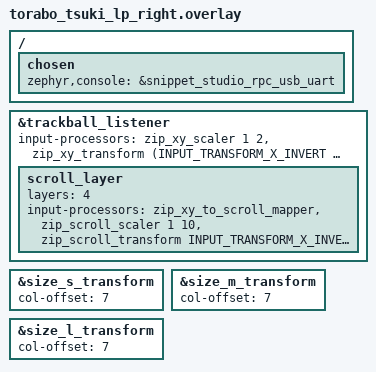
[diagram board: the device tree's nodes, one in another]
#include "torabo_tsuki_lp.dtsi"
#include <input/processors.dtsi>
#include <dt-bindings/zmk/input_transform.h>

/ {
	chosen {
		zephyr,console = &snippet_studio_rpc_usb_uart;
	};
};

&trackball_listener {
    input-processors = <&zip_xy_scaler 1 2
                        &zip_xy_transform (INPUT_TRANSFORM_X_INVERT | INPUT_TRANSFORM_Y_INVERT)>;

    scroll_layer {
        layers = <4>;
        input-processors = <&zip_xy_to_scroll_mapper
                            &zip_scroll_scaler 1 10
                            &zip_scroll_transform INPUT_TRANSFORM_X_INVERT>;
    };
};

&size_s_transform {
    col-offset = <7>;
};

&size_m_transform {
    col-offset = <7>;
};

&size_l_transform {
    col-offset = <7>;
};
